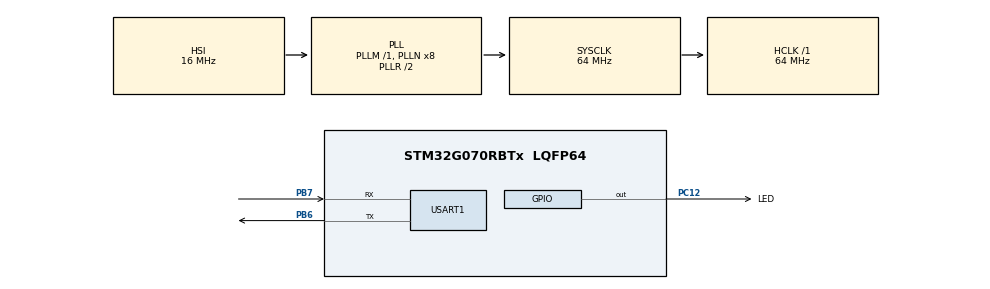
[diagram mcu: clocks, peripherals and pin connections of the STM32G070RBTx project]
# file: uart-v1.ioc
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Mcu.Family=STM32G0
Mcu.Name=STM32G070RBTx
Mcu.Package=LQFP64
PA13.Mode=Serial_Wire
PA13.Signal=SYS_SWDIO
PA14-BOOT0.Mode=Serial_Wire
PA14-BOOT0.Signal=SYS_SWCLK
PB6.Mode=Asynchronous
PB6.Signal=USART1_TX
PB7.Mode=Asynchronous
PB7.Signal=USART1_RX
PC12.GPIO_Label=LED
PC12.Signal=GPIO_Output
ProjectManager.HeapSize=0x200
ProjectManager.StackSize=0x400
ProjectManager.TargetToolchain=CMake
RCC.ADCFreq_Value=64000000
RCC.AHBFreq_Value=64000000
RCC.CortexFreq_Value=64000000
RCC.EXTERNAL_CLOCK_VALUE=48000
RCC.HCLKFreq_Value=64000000
RCC.HSE_VALUE=8000000
RCC.HSI_VALUE=16000000
RCC.LSE_VALUE=32768
RCC.SYSCLKFreq_VALUE=64000000
RCC.SYSCLKSource=RCC_SYSCLKSOURCE_PLLCLK
RCC.VCOOutputFreq_Value=128000000
USART1.VirtualMode-Asynchronous=VM_ASYNC
board=custom

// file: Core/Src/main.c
/* USER CODE BEGIN Header */
/**
 ******************************************************************************
 * @file           : main.c
 * @brief          : Main program body
 ******************************************************************************
 * @attention
 *
 * Copyright (c) 2025 STMicroelectronics.
 * All rights reserved.
 *
 * This software is licensed under terms that can be found in the LICENSE file
 * in the root directory of this software component.
 * If no LICENSE file comes with this software, it is provided AS-IS.
 *
 ******************************************************************************
 */
/* USER CODE END Header */
#include "main.h"
#include "gpio.h"
#include "stm32g0xx_hal_def.h"
#include "stm32g0xx_hal_uart.h"
#include "usart.h"
#include <stdint.h>
#include <string.h>

void SystemClock_Config(void);

int main(void) {

  /* MCU Configuration--------------------------------------------------------*/

  /* Reset of all peripherals, Initializes the Flash interface and the Systick.
   */
  HAL_Init();

  /* Configure the system clock */
  SystemClock_Config();

  /* Initialize all configured peripherals */
  MX_GPIO_Init();
  MX_USART1_UART_Init();

  /* Infinite loop */
  while (1) {

    /* USER CODE BEGIN 3 */
    HAL_GPIO_WritePin(LED_GPIO_Port, LED_Pin, GPIO_PIN_RESET);
    HAL_Delay(300);
    HAL_GPIO_WritePin(LED_GPIO_Port, LED_Pin, GPIO_PIN_SET);
    HAL_Delay(300);

    char test_output[] = "Hello MonkeyPi.\r\n";
    HAL_UART_Transmit(&huart1, (const uint8_t *)test_output,
                      strlen(test_output), HAL_MAX_DELAY);
  }
  /* USER CODE END 3 */
}

void SystemClock_Config(void) {
  RCC_OscInitTypeDef RCC_OscInitStruct = {0};
  RCC_ClkInitTypeDef RCC_ClkInitStruct = {0};

  /** Configure the main internal regulator output voltage
   */
  HAL_PWREx_ControlVoltageScaling(PWR_REGULATOR_VOLTAGE_SCALE1);

  /** Initializes the RCC Oscillators according to the specified parameters
   * in the RCC_OscInitTypeDef structure.
   */
  RCC_OscInitStruct.OscillatorType = RCC_OSCILLATORTYPE_HSI;
  RCC_OscInitStruct.HSIState = RCC_HSI_ON;
  RCC_OscInitStruct.HSIDiv = RCC_HSI_DIV1;
  RCC_OscInitStruct.HSICalibrationValue = RCC_HSICALIBRATION_DEFAULT;
  RCC_OscInitStruct.PLL.PLLState = RCC_PLL_ON;
  RCC_OscInitStruct.PLL.PLLSource = RCC_PLLSOURCE_HSI;
  RCC_OscInitStruct.PLL.PLLM = RCC_PLLM_DIV1;
  RCC_OscInitStruct.PLL.PLLN = 8;
  RCC_OscInitStruct.PLL.PLLP = RCC_PLLP_DIV2;
  RCC_OscInitStruct.PLL.PLLR = RCC_PLLR_DIV2;
  if (HAL_RCC_OscConfig(&RCC_OscInitStruct) != HAL_OK) {
    Error_Handler();
  }

  /** Initializes the CPU, AHB and APB buses clocks
   */
  RCC_ClkInitStruct.ClockType =
      RCC_CLOCKTYPE_HCLK | RCC_CLOCKTYPE_SYSCLK | RCC_CLOCKTYPE_PCLK1;
  RCC_ClkInitStruct.SYSCLKSource = RCC_SYSCLKSOURCE_PLLCLK;
  RCC_ClkInitStruct.AHBCLKDivider = RCC_SYSCLK_DIV1;
  RCC_ClkInitStruct.APB1CLKDivider = RCC_HCLK_DIV1;

  if (HAL_RCC_ClockConfig(&RCC_ClkInitStruct, FLASH_LATENCY_2) != HAL_OK) {
    Error_Handler();
  }
}

void Error_Handler(void) {
  __disable_irq();
  while (1) {
  }
}

#ifdef USE_FULL_ASSERT
/**
 * @brief  Reports the name of the source file and the source line number
 *         where the assert_param error has occurred.
 * @param  file: pointer to the source file name
 * @param  line: assert_param error line source number
 * @retval None
 */
void assert_failed(uint8_t *file, uint32_t line) {
  /* USER CODE BEGIN 6 */
  /* User can add his own implementation to report the file name and line
     number, ex: printf("Wrong parameters value: file %s on line %d\r\n", file,
     line) */
  /* USER CODE END 6 */
}
#endif /* USE_FULL_ASSERT */
